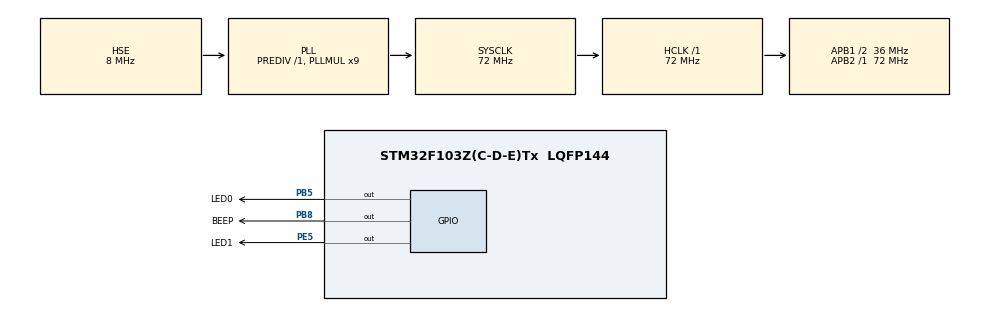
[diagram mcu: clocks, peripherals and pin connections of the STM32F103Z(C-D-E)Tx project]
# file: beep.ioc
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Mcu.Family=STM32F1
Mcu.Name=STM32F103Z(C-D-E)Tx
Mcu.Package=LQFP144
NVIC.PriorityGroup=NVIC_PRIORITYGROUP_4
OSC_IN.Mode=HSE-External-Oscillator
OSC_IN.Signal=RCC_OSC_IN
OSC_OUT.Mode=HSE-External-Oscillator
OSC_OUT.Signal=RCC_OSC_OUT
PA13.Mode=Serial_Wire
PA13.Signal=SYS_JTMS-SWDIO
PA14.Mode=Serial_Wire
PA14.Signal=SYS_JTCK-SWCLK
PB5.GPIO_Label=LED0
PB5.PinState=GPIO_PIN_SET
PB5.Signal=GPIO_Output
PB8.GPIO_Label=BEEP
PB8.Signal=GPIO_Output
PE5.GPIO_Label=LED1
PE5.PinState=GPIO_PIN_SET
PE5.Signal=GPIO_Output
ProjectManager.HeapSize=0x200
ProjectManager.StackSize=0x400
ProjectManager.TargetToolchain=SW4STM32
RCC.AHBFreq_Value=72000000
RCC.APB1CLKDivider=RCC_HCLK_DIV2
RCC.APB1Freq_Value=36000000
RCC.APB1TimFreq_Value=72000000
RCC.APB2Freq_Value=72000000
RCC.APB2TimFreq_Value=72000000
RCC.HCLKFreq_Value=72000000
RCC.PLLMUL=RCC_PLL_MUL9
RCC.PLLSourceVirtual=RCC_PLLSOURCE_HSE
RCC.SYSCLKFreq_VALUE=72000000
RCC.SYSCLKSource=RCC_SYSCLKSOURCE_PLLCLK
RCC.USBFreq_Value=72000000
board=custom

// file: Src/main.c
/* USER CODE BEGIN Header */
/**
  ******************************************************************************
  * @file           : main.c
  * @brief          : Main program body
  ******************************************************************************
  * @attention
  *
  * <h2><center>&copy; Copyright (c) 2019 STMicroelectronics.
  * All rights reserved.</center></h2>
  *
  * This software component is licensed by ST under BSD 3-Clause license,
  * the "License"; You may not use this file except in compliance with the
  * License. You may obtain a copy of the License at:
  *                        opensource.org/licenses/BSD-3-Clause
  *
  ******************************************************************************
  */
/* USER CODE END Header */

#include "main.h"

void SystemClock_Config(void);
static void MX_GPIO_Init(void);

int main(void)
{

  /* MCU Configuration--------------------------------------------------------*/

  /* Reset of all peripherals, Initializes the Flash interface and the Systick. */
  HAL_Init();

  /* Configure the system clock */
  SystemClock_Config();

  /* Initialize all configured peripherals */
  MX_GPIO_Init();

  /* Infinite loop */
  /* USER CODE BEGIN WHILE */
  while (1)
  {
      //反转BEEP输出电平
      HAL_GPIO_TogglePin(BEEP_GPIO_Port, BEEP_Pin);
      //延时1s
      HAL_Delay(1000);
    /* USER CODE END WHILE */

  }
}

void SystemClock_Config(void)
{
  RCC_OscInitTypeDef RCC_OscInitStruct = {0};
  RCC_ClkInitTypeDef RCC_ClkInitStruct = {0};

  /** Initializes the CPU, AHB and APB busses clocks
  */
  RCC_OscInitStruct.OscillatorType = RCC_OSCILLATORTYPE_HSE;
  RCC_OscInitStruct.HSEState = RCC_HSE_ON;
  RCC_OscInitStruct.HSEPredivValue = RCC_HSE_PREDIV_DIV1;
  RCC_OscInitStruct.HSIState = RCC_HSI_ON;
  RCC_OscInitStruct.PLL.PLLState = RCC_PLL_ON;
  RCC_OscInitStruct.PLL.PLLSource = RCC_PLLSOURCE_HSE;
  RCC_OscInitStruct.PLL.PLLMUL = RCC_PLL_MUL9;
  if (HAL_RCC_OscConfig(&RCC_OscInitStruct) != HAL_OK)
  {
    Error_Handler();
  }
  /** Initializes the CPU, AHB and APB busses clocks
  */
  RCC_ClkInitStruct.ClockType = RCC_CLOCKTYPE_HCLK|RCC_CLOCKTYPE_SYSCLK
                              |RCC_CLOCKTYPE_PCLK1|RCC_CLOCKTYPE_PCLK2;
  RCC_ClkInitStruct.SYSCLKSource = RCC_SYSCLKSOURCE_PLLCLK;
  RCC_ClkInitStruct.AHBCLKDivider = RCC_SYSCLK_DIV1;
  RCC_ClkInitStruct.APB1CLKDivider = RCC_HCLK_DIV2;
  RCC_ClkInitStruct.APB2CLKDivider = RCC_HCLK_DIV1;

  if (HAL_RCC_ClockConfig(&RCC_ClkInitStruct, FLASH_LATENCY_2) != HAL_OK)
  {
    Error_Handler();
  }
}

static void MX_GPIO_Init(void)
{
  GPIO_InitTypeDef GPIO_InitStruct = {0};

  /* GPIO Ports Clock Enable */
  __HAL_RCC_GPIOE_CLK_ENABLE();
  __HAL_RCC_GPIOA_CLK_ENABLE();
  __HAL_RCC_GPIOB_CLK_ENABLE();

  /*Configure GPIO pin Output Level */
  HAL_GPIO_WritePin(LED1_GPIO_Port, LED1_Pin, GPIO_PIN_SET);

  /*Configure GPIO pin Output Level */
  HAL_GPIO_WritePin(LED0_GPIO_Port, LED0_Pin, GPIO_PIN_SET);

  /*Configure GPIO pin Output Level */
  HAL_GPIO_WritePin(BEEP_GPIO_Port, BEEP_Pin, GPIO_PIN_RESET);

  /*Configure GPIO pin : LED1_Pin */
  GPIO_InitStruct.Pin = LED1_Pin;
  GPIO_InitStruct.Mode = GPIO_MODE_OUTPUT_PP;
  GPIO_InitStruct.Pull = GPIO_NOPULL;
  GPIO_InitStruct.Speed = GPIO_SPEED_FREQ_LOW;
  HAL_GPIO_Init(LED1_GPIO_Port, &GPIO_InitStruct);

  /*Configure GPIO pins : LED0_Pin BEEP_Pin */
  GPIO_InitStruct.Pin = LED0_Pin|BEEP_Pin;
  GPIO_InitStruct.Mode = GPIO_MODE_OUTPUT_PP;
  GPIO_InitStruct.Pull = GPIO_NOPULL;
  GPIO_InitStruct.Speed = GPIO_SPEED_FREQ_LOW;
  HAL_GPIO_Init(GPIOB, &GPIO_InitStruct);

}

void Error_Handler(void)
{
}

/************************ (C) COPYRIGHT STMicroelectronics *****END OF FILE****/
